# STM32F446MCY6 register map
File version: 1.0
Registers are 32-bit, access not given, reset 0x0 unless marked. A register's access mark holds for its fields unless they carry their own. Offsets are from the block's base; [hi:lo] are bit positions; {n}, {i} and the like mark numbered series.

## PWR
Base 0x40007000
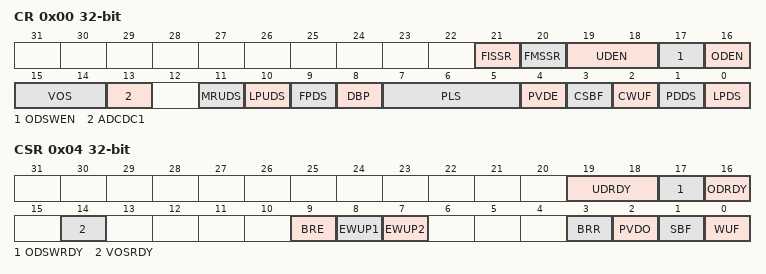
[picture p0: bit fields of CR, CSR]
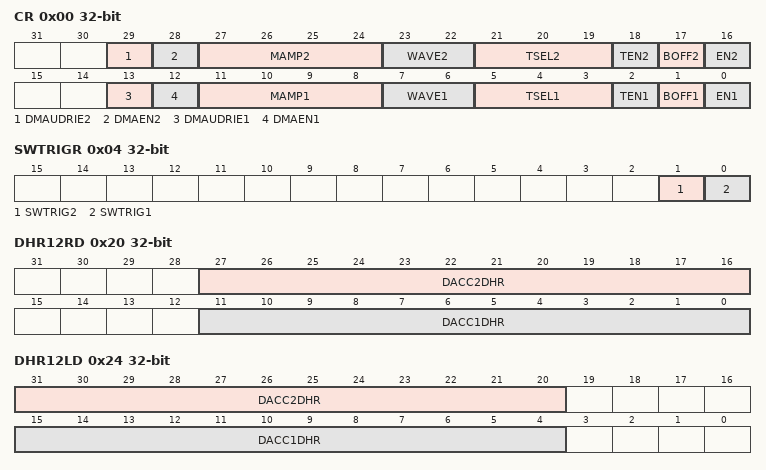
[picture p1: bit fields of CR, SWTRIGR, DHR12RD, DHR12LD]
0x00 CR
  [21] FISSR, [20] FMSSR, [19:18] UDEN, [17] ODSWEN, [16] ODEN, [15:14] VOS, [13] ADCDC1, [11] MRUDS, [10] LPUDS, [9] FPDS, [8] DBP, [7:5] PLS, [4] PVDE, [3] CSBF, [2] CWUF, [1] PDDS, [0] LPDS
0x04 CSR
  [19:18] UDRDY, [17] ODSWRDY, [16] ODRDY, [14] VOSRDY, [9] BRE, [8] EWUP1, [7] EWUP2, [3] BRR, [2] PVDO, [1] SBF, [0] WUF

## DAC
Base 0x40007400
0x00 CR
  [29] DMAUDRIE2, [28] DMAEN2, [27:24] MAMP2, [23:22] WAVE2, [21:19] TSEL2, [18] TEN2, [17] BOFF2, [16] EN2, [13] DMAUDRIE1, [12] DMAEN1, [11:8] MAMP1, [7:6] WAVE1, [5:3] TSEL1, [2] TEN1, [1] BOFF1, [0] EN1
0x04 SWTRIGR
  [1] SWTRIG2, [0] SWTRIG1
0x08 DHR12R1
  [11:0] DACC1DHR
0x0C DHR12L1
  [15:4] DACC1DHR
0x10 DHR8R1
  [7:0] DACC1DHR
0x14 DHR12R2
  [11:0] DACC2DHR
0x18 DHR12L2
  [15:4] DACC2DHR
0x1C DHR8R2
  [7:0] DACC2DHR
0x20 DHR12RD
  [27:16] DACC2DHR, [11:0] DACC1DHR
0x24 DHR12LD
  [31:20] DACC2DHR, [15:4] DACC1DHR
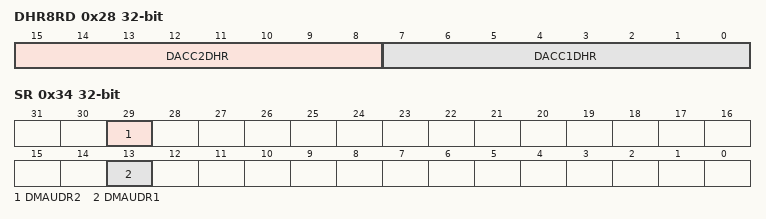
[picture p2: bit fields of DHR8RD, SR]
0x28 DHR8RD
  [15:8] DACC2DHR, [7:0] DACC1DHR
0x2C DOR1
  [11:0] DACC1DOR
0x30 DOR2
  [11:0] DACC2DOR
0x34 SR
  [29] DMAUDR2, [13] DMAUDR1

## TIM1
Base 0x40010000
Same registers: TIM8 0x40010400
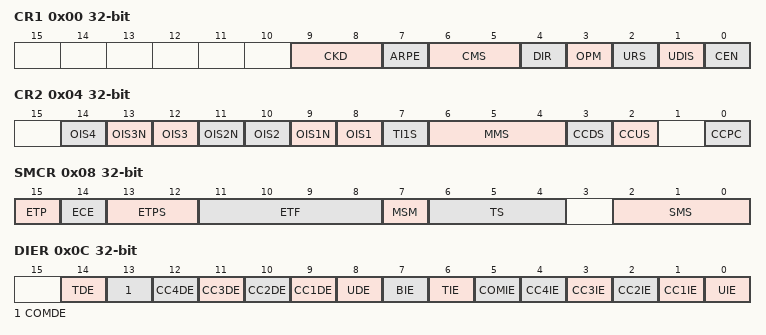
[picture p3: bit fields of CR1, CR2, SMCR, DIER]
0x00 CR1
  [9:8] CKD, [7] ARPE, [6:5] CMS, [4] DIR, [3] OPM, [2] URS, [1] UDIS, [0] CEN
0x04 CR2
  [2n+6] OIS{n} (n=1..4), [13] OIS3N, [11] OIS2N, [9] OIS1N, [7] TI1S, [6:4] MMS, [3] CCDS, [2] CCUS, [0] CCPC
0x08 SMCR
  [15] ETP, [14] ECE, [13:12] ETPS, [11:8] ETF, [7] MSM, [6:4] TS, [2:0] SMS
0x0C DIER
  [14] TDE, [13] COMDE, [n+8] CC{n}DE (n=1..4), [8] UDE, [7] BIE, [6] TIE, [5] COMIE, [n] CC{n}IE (n=1..4), [0] UIE
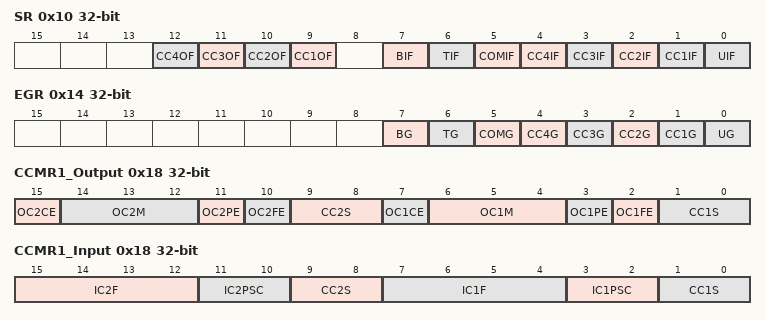
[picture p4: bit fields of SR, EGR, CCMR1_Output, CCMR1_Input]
0x10 SR
  [n+8] CC{n}OF (n=1..4), [7] BIF, [6] TIF, [5] COMIF, [n] CC{n}IF (n=1..4), [0] UIF
0x14 EGR
  [7] BG, [6] TG, [5] COMG, [n] CC{n}G (n=1..4), [0] UG
0x18 CCMR1_Output
  [15] OC2CE, [14:12] OC2M, [11] OC2PE, [10] OC2FE, [9:8] CC2S, [7] OC1CE, [6:4] OC1M, [3] OC1PE, [2] OC1FE, [1:0] CC1S
0x18 CCMR1_Input
  [15:12] IC2F, [11:10] IC2PSC, [9:8] CC2S, [7:4] IC1F, [3:2] IC1PSC, [1:0] CC1S
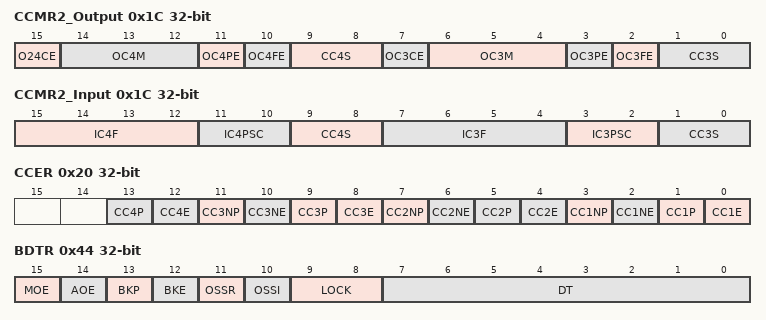
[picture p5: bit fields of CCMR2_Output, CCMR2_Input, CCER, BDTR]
0x1C CCMR2_Output
  [15] O24CE, [14:12] OC4M, [11] OC4PE, [10] OC4FE, [9:8] CC4S, [7] OC3CE, [6:4] OC3M, [3] OC3PE, [2] OC3FE, [1:0] CC3S
0x1C CCMR2_Input
  [15:12] IC4F, [11:10] IC4PSC, [9:8] CC4S, [7:4] IC3F, [3:2] IC3PSC, [1:0] CC3S
0x20 CCER
  [4n-3] CC{n}P (n=1..4), [4n-4] CC{n}E (n=1..4), [11] CC3NP, [10] CC3NE, [7] CC2NP, [6] CC2NE, [3] CC1NP, [2] CC1NE
0x24 CNT
  [15:0] CNT
0x28 PSC
  [15:0] PSC
0x2C ARR
  [15:0] ARR
0x30 RCR
  [7:0] REP
{0x30+4i} CCR{i} (i=1..4)
  [15:0] CCR{i}
0x44 BDTR
  [15] MOE, [14] AOE, [13] BKP, [12] BKE, [11] OSSR, [10] OSSI, [9:8] LOCK, [7:0] DT
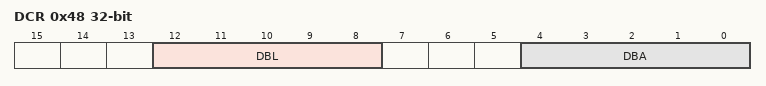
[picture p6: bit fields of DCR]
0x48 DCR
  [12:8] DBL, [4:0] DBA
0x4C DMAR
  [15:0] DMAB

## ADC1
Base 0x40012000
Same registers: ADC2 0x40012100, ADC3 0x40012300
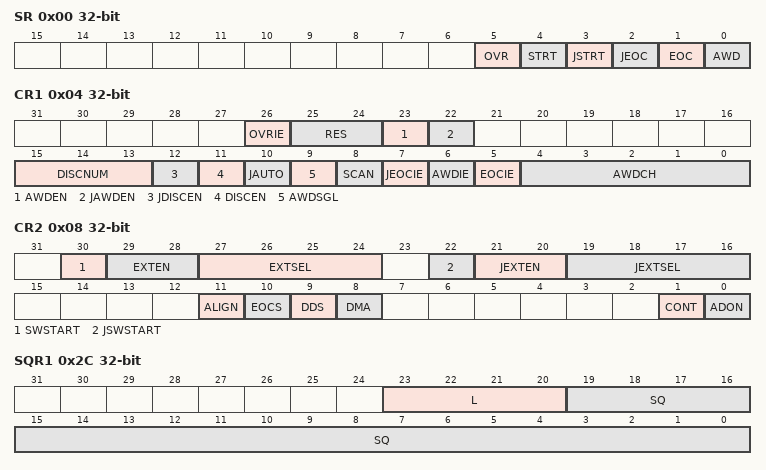
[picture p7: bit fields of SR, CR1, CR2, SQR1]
0x00 SR
  [5] OVR, [4] STRT, [3] JSTRT, [2] JEOC, [1] EOC, [0] AWD
0x04 CR1
  [26] OVRIE, [25:24] RES, [23] AWDEN, [22] JAWDEN, [15:13] DISCNUM, [12] JDISCEN, [11] DISCEN, [10] JAUTO, [9] AWDSGL, [8] SCAN, [7] JEOCIE, [6] AWDIE, [5] EOCIE, [4:0] AWDCH
0x08 CR2
  [30] SWSTART, [29:28] EXTEN, [27:24] EXTSEL, [22] JSWSTART, [21:20] JEXTEN, [19:16] JEXTSEL, [11] ALIGN, [10] EOCS, [9] DDS, [8] DMA, [1] CONT, [0] ADON
0x0C SMPR1
  [31:0] SMP
0x10 SMPR2
  [31:0] SMP
{0x10+4i} JOFR{i} (i=1..4)
  [11:0] JOFFSET{i}
0x24 HTR
  [11:0] HT
0x28 LTR
  [11:0] LT
0x2C SQR1
  [23:20] L, [19:0] SQ
0x30 SQR2
  [29:0] SQ
0x34 SQR3
  [29:0] SQ
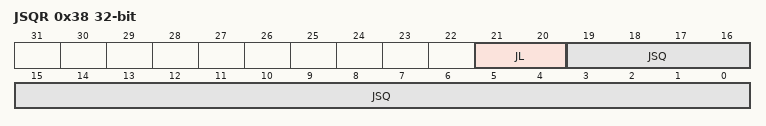
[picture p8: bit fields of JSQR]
0x38 JSQR
  [21:20] JL, [19:0] JSQ
{0x38+4i} JDR{i} (i=1..4)
  [15:0] JDATA
0x4C DR
  [15:0] DATA

## SDMMC
Base 0x40012C00
0x00 POWER
  [1:0] PWRCTRL
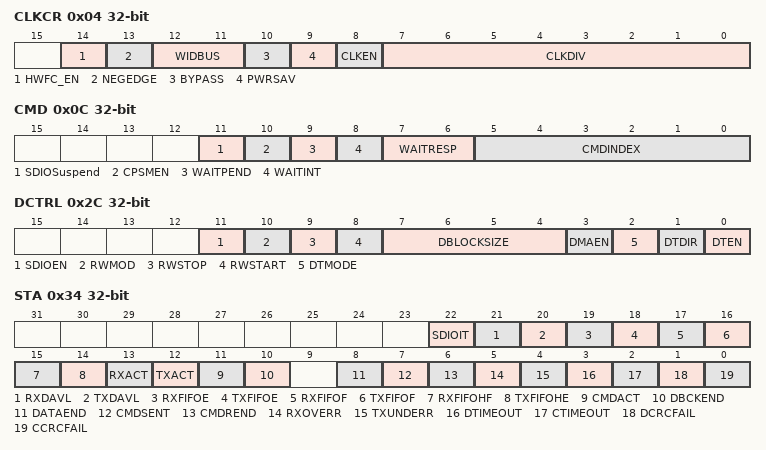
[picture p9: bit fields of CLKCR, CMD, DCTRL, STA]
0x04 CLKCR
  [14] HWFC_EN, [13] NEGEDGE, [12:11] WIDBUS, [10] BYPASS, [9] PWRSAV, [8] CLKEN, [7:0] CLKDIV
0x08 ARG
  [31:0] CMDARG
0x0C CMD
  [11] SDIOSuspend, [10] CPSMEN, [9] WAITPEND, [8] WAITINT, [7:6] WAITRESP, [5:0] CMDINDEX
0x10 RESPCMD
  [5:0] RESPCMD
{0x10+4i} RESP{i} (i=1..4)
  [31:0] CARDSTATUS{i}
0x24 DTIMER
  [31:0] DATATIME
0x28 DLEN
  [24:0] DATALENGTH
0x2C DCTRL
  [11] SDIOEN, [10] RWMOD, [9] RWSTOP, [8] RWSTART, [7:4] DBLOCKSIZE, [3] DMAEN, [2] DTMODE, [1] DTDIR, [0] DTEN
0x30 DCOUNT
  [24:0] DATACOUNT
0x34 STA
  [22] SDIOIT, [21] RXDAVL, [20] TXDAVL, [19] RXFIFOE, [18] TXFIFOE, [17] RXFIFOF, [16] TXFIFOF, [15] RXFIFOHF, [14] TXFIFOHE, [13] RXACT, [12] TXACT, [11] CMDACT, [10] DBCKEND, [8] DATAEND, [7] CMDSENT, [6] CMDREND, [5] RXOVERR, [4] TXUNDERR, [3] DTIMEOUT, [2] CTIMEOUT, [1] DCRCFAIL, [0] CCRCFAIL
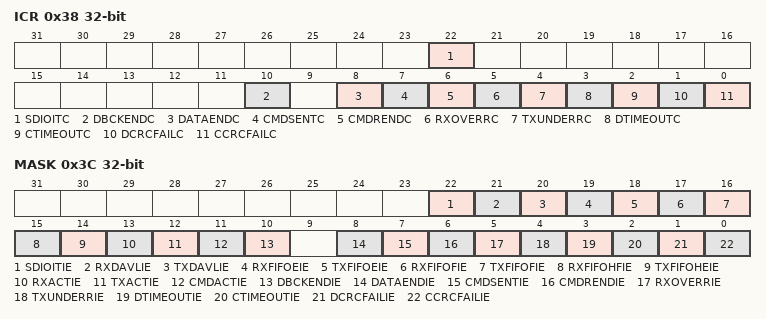
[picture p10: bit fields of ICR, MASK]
0x38 ICR
  [22] SDIOITC, [10] DBCKENDC, [8] DATAENDC, [7] CMDSENTC, [6] CMDRENDC, [5] RXOVERRC, [4] TXUNDERRC, [3] DTIMEOUTC, [2] CTIMEOUTC, [1] DCRCFAILC, [0] CCRCFAILC
0x3C MASK
  [22] SDIOITIE, [21] RXDAVLIE, [20] TXDAVLIE, [19] RXFIFOEIE, [18] TXFIFOEIE, [17] RXFIFOFIE, [16] TXFIFOFIE, [15] RXFIFOHFIE, [14] TXFIFOHEIE, [13] RXACTIE, [12] TXACTIE, [11] CMDACTIE, [10] DBCKENDIE, [8] DATAENDIE, [7] CMDSENTIE, [6] CMDRENDIE, [5] RXOVERRIE, [4] TXUNDERRIE, [3] DTIMEOUTIE, [2] CTIMEOUTIE, [1] DCRCFAILIE, [0] CCRCFAILIE
0x48 FIFOCNT
  [23:0] FIFOCOUNT
0x80 FIFO
  [31:0] FIF0Data
